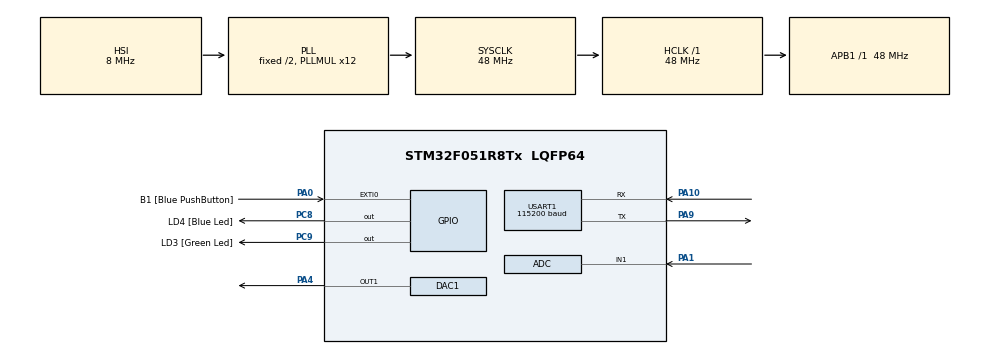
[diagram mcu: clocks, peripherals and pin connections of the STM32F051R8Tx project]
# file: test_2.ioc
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Dma.ADC.0.Direction=DMA_PERIPH_TO_MEMORY
Dma.ADC.0.Instance=DMA1_Channel1
Dma.ADC.0.MemDataAlignment=DMA_MDATAALIGN_HALFWORD
Dma.ADC.0.MemInc=DMA_MINC_ENABLE
Dma.ADC.0.Mode=DMA_NORMAL
Dma.ADC.0.PeriphDataAlignment=DMA_PDATAALIGN_HALFWORD
Dma.ADC.0.PeriphInc=DMA_PINC_DISABLE
Dma.ADC.0.Priority=DMA_PRIORITY_LOW
Dma.Request0=ADC
FREERTOS.Tasks01=defaultTask,0,128,StartDefaultTask,Default,NULL,Dynamic,NULL,NULL;cmdParse,-3,128,StartTask02,Default,NULL,Dynamic,NULL,NULL
Mcu.Family=STM32F0
Mcu.Name=STM32F051R8Tx
Mcu.Package=LQFP64
NVIC.DMA1_Channel1_IRQn=true\:3\:0\:false\:false\:true\:true\:false
NVIC.TIM1_BRK_UP_TRG_COM_IRQn=true\:0\:0\:false\:false\:true\:false\:false
NVIC.TimeBase=TIM1_BRK_UP_TRG_COM_IRQn
NVIC.TimeBaseIP=TIM1
NVIC.USART1_IRQn=true\:3\:0\:false\:false\:true\:true\:true
PA0.GPIO_Label=B1 [Blue PushButton]
PA0.GPIO_ModeDefaultEXTI=GPIO_MODE_EVT_RISING
PA0.Signal=GPXTI0
PA1.Mode=IN1
PA1.Signal=ADC_IN1
PA10.Mode=Asynchronous
PA10.Signal=USART1_RX
PA13.GPIO_Label=SWDIO
PA13.Mode=Serial_Wire
PA13.Signal=SYS_SWDIO
PA14.GPIO_Label=SWCLK
PA14.Mode=Serial_Wire
PA14.Signal=SYS_SWCLK
PA4.Signal=COMP_DAC11_group
PA9.Mode=Asynchronous
PA9.Signal=USART1_TX
PC8.GPIO_Label=LD4 [Blue Led]
PC8.Signal=GPIO_Output
PC9.GPIO_Label=LD3 [Green Led]
PC9.Signal=GPIO_Output
ProjectManager.HeapSize=0x200
ProjectManager.StackSize=0x400
ProjectManager.TargetToolchain=SW4STM32
RCC.AHBFreq_Value=48000000
RCC.APB1Freq_Value=48000000
RCC.APB1TimFreq_Value=48000000
RCC.HCLKFreq_Value=48000000
RCC.PLLMUL=RCC_PLL_MUL12
RCC.SYSCLKFreq_VALUE=48000000
RCC.SYSCLKSource=RCC_SYSCLKSOURCE_PLLCLK
SH.COMP_DAC11_group.0=DAC1_OUT1,DAC_OUT1
USART1.BaudRate=115200
USART1.VirtualMode-Asynchronous=VM_ASYNC
VP_FREERTOS_VS_ENABLE.Mode=Enabled
VP_SYS_VS_tim1.Mode=TIM1
board=STM32F0DISCOVERY

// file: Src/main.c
/**
  ******************************************************************************
  * @file           : main.c
  * @brief          : Main program body
  ******************************************************************************
  * This notice applies to any and all portions of this file
  * that are not between comment pairs USER CODE BEGIN and
  * USER CODE END. Other portions of this file, whether
  * inserted by the user or by software development tools
  * are owned by their respective copyright owners.
  *
  * Copyright (c) 2018 STMicroelectronics International N.V.
  * All rights reserved.
  *
  * Redistribution and use in source and binary forms, with or without
  * modification, are permitted, provided that the following conditions are met:
  *
  * 1. Redistribution of source code must retain the above copyright notice,
  *    this list of conditions and the following disclaimer.
  * 2. Redistributions in binary form must reproduce the above copyright notice,
  *    this list of conditions and the following disclaimer in the documentation
  *    and/or other materials provided with the distribution.
  * 3. Neither the name of STMicroelectronics nor the names of other
  *    contributors to this software may be used to endorse or promote products
  *    derived from this software without specific written permission.
  * 4. This software, including modifications and/or derivative works of this
  *    software, must execute solely and exclusively on microcontroller or
  *    microprocessor devices manufactured by or for STMicroelectronics.
  * 5. Redistribution and use of this software other than as permitted under
  *    this license is void and will automatically terminate your rights under
  *    this license.
  *
  * THIS SOFTWARE IS PROVIDED BY STMICROELECTRONICS AND CONTRIBUTORS "AS IS"
  * AND ANY EXPRESS, IMPLIED OR STATUTORY WARRANTIES, INCLUDING, BUT NOT
  * LIMITED TO, THE IMPLIED WARRANTIES OF MERCHANTABILITY, FITNESS FOR A
  * PARTICULAR PURPOSE AND NON-INFRINGEMENT OF THIRD PARTY INTELLECTUAL PROPERTY
  * RIGHTS ARE DISCLAIMED TO THE FULLEST EXTENT PERMITTED BY LAW. IN NO EVENT
  * SHALL STMICROELECTRONICS OR CONTRIBUTORS BE LIABLE FOR ANY DIRECT, INDIRECT,
  * INCIDENTAL, SPECIAL, EXEMPLARY, OR CONSEQUENTIAL DAMAGES (INCLUDING, BUT NOT
  * LIMITED TO, PROCUREMENT OF SUBSTITUTE GOODS OR SERVICES; LOSS OF USE, DATA,
  * OR PROFITS; OR BUSINESS INTERRUPTION) HOWEVER CAUSED AND ON ANY THEORY OF
  * LIABILITY, WHETHER IN CONTRACT, STRICT LIABILITY, OR TORT (INCLUDING
  * NEGLIGENCE OR OTHERWISE) ARISING IN ANY WAY OUT OF THE USE OF THIS SOFTWARE,
  * EVEN IF ADVISED OF THE POSSIBILITY OF SUCH DAMAGE.
  *
  ******************************************************************************
  */
#include "main.h"
#include "stm32f0xx_hal.h"
#include "cmsis_os.h"

/* USER CODE BEGIN Includes */
#include "cmd/cmd.h"
/* USER CODE END Includes */

ADC_HandleTypeDef hadc;
DMA_HandleTypeDef hdma_adc;

DAC_HandleTypeDef hdac1;

UART_HandleTypeDef huart1;

osThreadId defaultTaskHandle;
osThreadId cmdParseHandle;

/* USER CODE BEGIN PV */
/* Private variables ---------------------------------------------------------*/

/* USER CODE END PV */

void SystemClock_Config(void);
static void MX_GPIO_Init(void);
static void MX_DMA_Init(void);
static void MX_DAC1_Init(void);
static void MX_ADC_Init(void);
static void MX_USART1_UART_Init(void);
void StartDefaultTask(void const * argument);
void StartTask02(void const * argument);

/* USER CODE BEGIN PFP */
/* Private function prototypes -----------------------------------------------*/

/* USER CODE END PFP */

int main(void)
{

  /* MCU Configuration----------------------------------------------------------*/

  /* Reset of all peripherals, Initializes the Flash interface and the Systick. */
  HAL_Init();

  /* Configure the system clock */
  SystemClock_Config();

  /* Initialize all configured peripherals */
  MX_GPIO_Init();
  MX_DMA_Init();
  MX_DAC1_Init();
  MX_ADC_Init();
  MX_USART1_UART_Init();

  /* Create the thread(s) */
  /* definition and creation of defaultTask */
  osThreadDef(defaultTask, StartDefaultTask, osPriorityNormal, 0, 128);
  defaultTaskHandle = osThreadCreate(osThread(defaultTask), NULL);

  /* definition and creation of cmdParse */
  osThreadDef(cmdParse, StartTask02, osPriorityIdle, 0, 128);
  cmdParseHandle = osThreadCreate(osThread(cmdParse), NULL);

  /* Start scheduler */
  osKernelStart();

  /* We should never get here as control is now taken by the scheduler */

  /* Infinite loop */
  while (1)
  {

  }

}

void SystemClock_Config(void)
{

  RCC_OscInitTypeDef RCC_OscInitStruct;
  RCC_ClkInitTypeDef RCC_ClkInitStruct;
  RCC_PeriphCLKInitTypeDef PeriphClkInit;

    /**Initializes the CPU, AHB and APB busses clocks
    */
  RCC_OscInitStruct.OscillatorType = RCC_OSCILLATORTYPE_HSI|RCC_OSCILLATORTYPE_HSI14;
  RCC_OscInitStruct.HSIState = RCC_HSI_ON;
  RCC_OscInitStruct.HSI14State = RCC_HSI14_ON;
  RCC_OscInitStruct.HSICalibrationValue = 16;
  RCC_OscInitStruct.HSI14CalibrationValue = 16;
  RCC_OscInitStruct.PLL.PLLState = RCC_PLL_ON;
  RCC_OscInitStruct.PLL.PLLSource = RCC_PLLSOURCE_HSI;
  RCC_OscInitStruct.PLL.PLLMUL = RCC_PLL_MUL12;
  RCC_OscInitStruct.PLL.PREDIV = RCC_PREDIV_DIV1;
  if (HAL_RCC_OscConfig(&RCC_OscInitStruct) != HAL_OK)
  {
    _Error_Handler(__FILE__, __LINE__);
  }

    /**Initializes the CPU, AHB and APB busses clocks
    */
  RCC_ClkInitStruct.ClockType = RCC_CLOCKTYPE_HCLK|RCC_CLOCKTYPE_SYSCLK
                              |RCC_CLOCKTYPE_PCLK1;
  RCC_ClkInitStruct.SYSCLKSource = RCC_SYSCLKSOURCE_PLLCLK;
  RCC_ClkInitStruct.AHBCLKDivider = RCC_SYSCLK_DIV1;
  RCC_ClkInitStruct.APB1CLKDivider = RCC_HCLK_DIV1;

  if (HAL_RCC_ClockConfig(&RCC_ClkInitStruct, FLASH_LATENCY_1) != HAL_OK)
  {
    _Error_Handler(__FILE__, __LINE__);
  }

  PeriphClkInit.PeriphClockSelection = RCC_PERIPHCLK_USART1;
  PeriphClkInit.Usart1ClockSelection = RCC_USART1CLKSOURCE_PCLK1;
  if (HAL_RCCEx_PeriphCLKConfig(&PeriphClkInit) != HAL_OK)
  {
    _Error_Handler(__FILE__, __LINE__);
  }

    /**Configure the Systick interrupt time
    */
  HAL_SYSTICK_Config(HAL_RCC_GetHCLKFreq()/1000);

    /**Configure the Systick
    */
  HAL_SYSTICK_CLKSourceConfig(SYSTICK_CLKSOURCE_HCLK);

  /* SysTick_IRQn interrupt configuration */
  HAL_NVIC_SetPriority(SysTick_IRQn, 3, 0);
}

/* ADC init function */
static void MX_ADC_Init(void)
{

  ADC_ChannelConfTypeDef sConfig;

    /**Configure the global features of the ADC (Clock, Resolution, Data Alignment and number of conversion)
    */
  hadc.Instance = ADC1;
  hadc.Init.ClockPrescaler = ADC_CLOCK_ASYNC_DIV1;
  hadc.Init.Resolution = ADC_RESOLUTION_12B;
  hadc.Init.DataAlign = ADC_DATAALIGN_RIGHT;
  hadc.Init.ScanConvMode = ADC_SCAN_DIRECTION_FORWARD;
  hadc.Init.EOCSelection = ADC_EOC_SINGLE_CONV;
  hadc.Init.LowPowerAutoWait = DISABLE;
  hadc.Init.LowPowerAutoPowerOff = DISABLE;
  hadc.Init.ContinuousConvMode = DISABLE;
  hadc.Init.DiscontinuousConvMode = DISABLE;
  hadc.Init.ExternalTrigConv = ADC_SOFTWARE_START;
  hadc.Init.ExternalTrigConvEdge = ADC_EXTERNALTRIGCONVEDGE_NONE;
  hadc.Init.DMAContinuousRequests = DISABLE;
  hadc.Init.Overrun = ADC_OVR_DATA_PRESERVED;
  if (HAL_ADC_Init(&hadc) != HAL_OK)
  {
    _Error_Handler(__FILE__, __LINE__);
  }

    /**Configure for the selected ADC regular channel to be converted.
    */
  sConfig.Channel = ADC_CHANNEL_1;
  sConfig.Rank = ADC_RANK_CHANNEL_NUMBER;
  sConfig.SamplingTime = ADC_SAMPLETIME_1CYCLE_5;
  if (HAL_ADC_ConfigChannel(&hadc, &sConfig) != HAL_OK)
  {
    _Error_Handler(__FILE__, __LINE__);
  }

}

/* DAC1 init function */
static void MX_DAC1_Init(void)
{

  DAC_ChannelConfTypeDef sConfig;

    /**DAC Initialization
    */
  hdac1.Instance = DAC;
  if (HAL_DAC_Init(&hdac1) != HAL_OK)
  {
    _Error_Handler(__FILE__, __LINE__);
  }

    /**DAC channel OUT1 config
    */
  sConfig.DAC_Trigger = DAC_TRIGGER_NONE;
  sConfig.DAC_OutputBuffer = DAC_OUTPUTBUFFER_ENABLE;
  if (HAL_DAC_ConfigChannel(&hdac1, &sConfig, DAC_CHANNEL_1) != HAL_OK)
  {
    _Error_Handler(__FILE__, __LINE__);
  }

}

/* USART1 init function */
static void MX_USART1_UART_Init(void)
{

  huart1.Instance = USART1;
  huart1.Init.BaudRate = 115200;
  huart1.Init.WordLength = UART_WORDLENGTH_8B;
  huart1.Init.StopBits = UART_STOPBITS_1;
  huart1.Init.Parity = UART_PARITY_NONE;
  huart1.Init.Mode = UART_MODE_TX_RX;
  huart1.Init.HwFlowCtl = UART_HWCONTROL_NONE;
  huart1.Init.OverSampling = UART_OVERSAMPLING_16;
  huart1.Init.OneBitSampling = UART_ONE_BIT_SAMPLE_DISABLE;
  huart1.AdvancedInit.AdvFeatureInit = UART_ADVFEATURE_NO_INIT;
  if (HAL_UART_Init(&huart1) != HAL_OK)
  {
    _Error_Handler(__FILE__, __LINE__);
  }

}

static void MX_DMA_Init(void)
{
  /* DMA controller clock enable */
  __HAL_RCC_DMA1_CLK_ENABLE();

  /* DMA interrupt init */
  /* DMA1_Channel1_IRQn interrupt configuration */
  HAL_NVIC_SetPriority(DMA1_Channel1_IRQn, 3, 0);
  HAL_NVIC_EnableIRQ(DMA1_Channel1_IRQn);

}

/** Configure pins as
        * Analog
        * Input
        * Output
        * EVENT_OUT
        * EXTI
*/
static void MX_GPIO_Init(void)
{

  GPIO_InitTypeDef GPIO_InitStruct;

  /* GPIO Ports Clock Enable */
  __HAL_RCC_GPIOA_CLK_ENABLE();
  __HAL_RCC_GPIOC_CLK_ENABLE();

  /*Configure GPIO pin Output Level */
  HAL_GPIO_WritePin(GPIOC, LD4_Pin|LD3_Pin, GPIO_PIN_RESET);

  /*Configure GPIO pin : B1_Pin */
  GPIO_InitStruct.Pin = B1_Pin;
  GPIO_InitStruct.Mode = GPIO_MODE_EVT_RISING;
  GPIO_InitStruct.Pull = GPIO_NOPULL;
  HAL_GPIO_Init(B1_GPIO_Port, &GPIO_InitStruct);

  /*Configure GPIO pins : LD4_Pin LD3_Pin */
  GPIO_InitStruct.Pin = LD4_Pin|LD3_Pin;
  GPIO_InitStruct.Mode = GPIO_MODE_OUTPUT_PP;
  GPIO_InitStruct.Pull = GPIO_NOPULL;
  GPIO_InitStruct.Speed = GPIO_SPEED_FREQ_LOW;
  HAL_GPIO_Init(GPIOC, &GPIO_InitStruct);

}

/* StartDefaultTask function */
void StartDefaultTask(void const * argument)
{

  for(;;)
  {
    osDelay(1);
  }
}

/* StartTask02 function */
void StartTask02(void const * argument)
{
  /* USER CODE BEGIN StartTask02 */
	 cmdInitUART();
  /* Infinite loop */
  for(;;)
  {
    osDelay(1);
  }
  /* USER CODE END StartTask02 */
}

void HAL_TIM_PeriodElapsedCallback(TIM_HandleTypeDef *htim)
{
  if (htim->Instance == TIM1) {
    HAL_IncTick();
  }
}

void _Error_Handler(char *file, int line)
{
  while(1)
  {
  }
}

/************************ (C) COPYRIGHT STMicroelectronics *****END OF FILE****/
